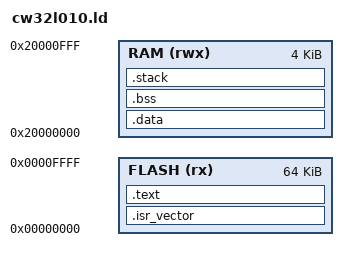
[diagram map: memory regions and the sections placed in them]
/* Linker script for CW32L010Y8M6 (64KB flash, 4KB SRAM) - sensor project */
MEMORY
{
    FLASH (rx)  : ORIGIN = 0x00000000, LENGTH = 64K
    RAM   (rwx) : ORIGIN = 0x20000000, LENGTH = 4K
}

/* 保留顶层页(0x0000FF80-0x0000FFFF)给参数 NVM 记录 (params.c) */
ENTRY(Reset_Handler)

SECTIONS
{
    .isr_vector :
    {
        . = ALIGN(4);
        KEEP(*(.isr_vector))
        . = ALIGN(4);
    } > FLASH

    .text :
    {
        . = ALIGN(4);
        *(.text)
        *(.text*)
        *(.rodata)
        *(.rodata*)
        . = ALIGN(4);
        _etext = .;
        _sidata = _etext;
    } > FLASH

    .data : AT(_etext)
    {
        . = ALIGN(4);
        _sdata = .;
        *(.data)
        *(.data*)
        . = ALIGN(4);
        _edata = .;
    } > RAM

    .bss :
    {
        . = ALIGN(4);
        _sbss = .;
        *(.bss)
        *(.bss*)
        *(COMMON)
        . = ALIGN(4);
        _ebss = .;
    } > RAM

    .stack (NOLOAD) :
    {
        . = ALIGN(8);
        . = . + 0x200;
        __StackTop = .;
    } > RAM

    /DISCARD/ :
    {
        libc.a(*)
        libm.a(*)
        libgcc.a(*)
        *(.init)
        *(.fini)
        *(.ARM.exidx*)
        *(.ARM.attributes)
    }
}
